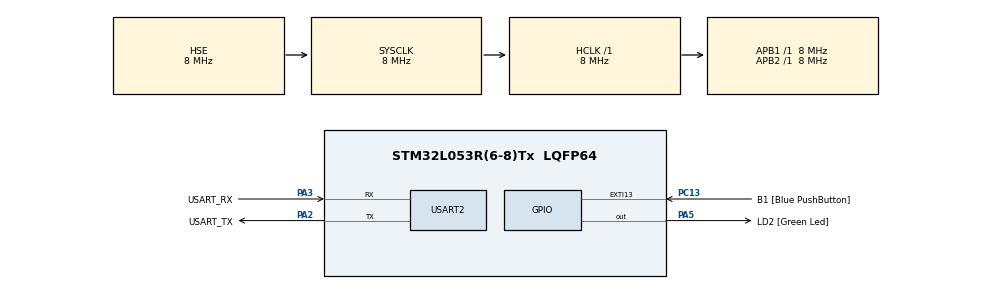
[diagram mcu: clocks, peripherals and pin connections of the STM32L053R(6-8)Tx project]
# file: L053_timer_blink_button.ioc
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Mcu.Family=STM32L0
Mcu.Name=STM32L053R(6-8)Tx
Mcu.Package=LQFP64
NVIC.TIM6_DAC_IRQn=true\:0\:0\:false\:false\:true\:true\:true
PA13.GPIO_Label=TMS
PA13.Mode=Serial_Wire
PA13.Signal=SYS_SWDIO
PA14.GPIO_Label=TCK
PA14.Mode=Serial_Wire
PA14.Signal=SYS_SWCLK
PA2.GPIO_Label=USART_TX
PA2.Mode=Asynchronous
PA2.Signal=USART2_TX
PA3.GPIO_Label=USART_RX
PA3.Mode=Asynchronous
PA3.Signal=USART2_RX
PA5.GPIO_Label=LD2 [Green Led]
PA5.Signal=GPIO_Output
PC13.GPIO_Label=B1 [Blue PushButton]
PC13.GPIO_ModeDefaultEXTI=GPIO_MODE_IT_FALLING
PC13.GPIO_PuPd=GPIO_PULLUP
PC13.Signal=GPXTI13
PC14-OSC32_IN.Mode=LSE-External-Oscillator
PC14-OSC32_IN.Signal=RCC_OSC32_IN
PC15-OSC32_OUT.Mode=LSE-External-Oscillator
PC15-OSC32_OUT.Signal=RCC_OSC32_OUT
PH0-OSC_IN.Mode=HSE-External-Clock-Source
PH0-OSC_IN.Signal=RCC_OSC_IN
PH1-OSC_OUT.Signal=RCC_OSC_OUT
ProjectManager.HeapSize=0x200
ProjectManager.StackSize=0x400
ProjectManager.TargetToolchain=STM32CubeIDE
RCC.AHBFreq_Value=8000000
RCC.APB1Freq_Value=8000000
RCC.APB1TimFreq_Value=8000000
RCC.APB2Freq_Value=8000000
RCC.APB2TimFreq_Value=8000000
RCC.HCLKFreq_Value=8000000
RCC.HSE_VALUE=8000000
RCC.HSI16_VALUE=16000000
RCC.HSI48_VALUE=48000000
RCC.HSI_VALUE=16000000
RCC.MSI_VALUE=2097000
RCC.PLLMUL=RCC_PLLMUL_4
RCC.SYSCLKFreq_VALUE=8000000
RCC.SYSCLKSource=RCC_SYSCLKSOURCE_HSE
RCC.VCOOutputFreq_Value=64000000
TIM6.Period=100
TIM6.Prescaler=8000
USART2.VirtualMode-Asynchronous=VM_ASYNC
VP_TIM6_VS_ClockSourceINT.Mode=Enable_Timer
board=NUCLEO-L053R8

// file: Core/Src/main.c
/* USER CODE BEGIN Header */
/**
  ******************************************************************************
  * @file           : main.c
  * @brief          : Main program body
  ******************************************************************************
  * @attention
  *
  * <h2><center>&copy; Copyright (c) 2020 STMicroelectronics.
  * All rights reserved.</center></h2>
  *
  * This software component is licensed by ST under BSD 3-Clause license,
  * the "License"; You may not use this file except in compliance with the
  * License. You may obtain a copy of the License at:
  *                        opensource.org/licenses/BSD-3-Clause
  *
  ******************************************************************************
  */
/* USER CODE END Header */

#include "main.h"

TIM_HandleTypeDef htim6;

UART_HandleTypeDef huart2;

void SystemClock_Config(void);
static void MX_GPIO_Init(void);
static void MX_USART2_UART_Init(void);
static void MX_TIM6_Init(void);

/* USER CODE BEGIN 0 */
int count = 0, x = 0;
/* USER CODE END 0 */

int main(void)
{

  /* MCU Configuration--------------------------------------------------------*/

  /* Reset of all peripherals, Initializes the Flash interface and the Systick. */
  HAL_Init();

  /* Configure the system clock */
  SystemClock_Config();

  /* Initialize all configured peripherals */
  MX_GPIO_Init();
  MX_USART2_UART_Init();
  MX_TIM6_Init();
  /* USER CODE BEGIN 2 */
  HAL_TIM_Base_Start_IT(&htim6);
  /* USER CODE END 2 */

  /* Infinite loop */
  /* USER CODE BEGIN WHILE */
  while (1)
  {
	  if(HAL_GPIO_ReadPin(B1_GPIO_Port, B1_Pin) == 0)
	  {
		  x = 1;
	  }
	  else
	  {
		  x = 5;
	  }
    /* USER CODE END WHILE */

  }
}

void SystemClock_Config(void)
{
  RCC_OscInitTypeDef RCC_OscInitStruct = {0};
  RCC_ClkInitTypeDef RCC_ClkInitStruct = {0};
  RCC_PeriphCLKInitTypeDef PeriphClkInit = {0};

  /** Configure the main internal regulator output voltage
  */
  __HAL_PWR_VOLTAGESCALING_CONFIG(PWR_REGULATOR_VOLTAGE_SCALE1);
  /** Initializes the CPU, AHB and APB busses clocks
  */
  RCC_OscInitStruct.OscillatorType = RCC_OSCILLATORTYPE_HSE;
  RCC_OscInitStruct.HSEState = RCC_HSE_BYPASS;
  RCC_OscInitStruct.PLL.PLLState = RCC_PLL_NONE;
  if (HAL_RCC_OscConfig(&RCC_OscInitStruct) != HAL_OK)
  {
    Error_Handler();
  }
  /** Initializes the CPU, AHB and APB busses clocks
  */
  RCC_ClkInitStruct.ClockType = RCC_CLOCKTYPE_HCLK|RCC_CLOCKTYPE_SYSCLK
                              |RCC_CLOCKTYPE_PCLK1|RCC_CLOCKTYPE_PCLK2;
  RCC_ClkInitStruct.SYSCLKSource = RCC_SYSCLKSOURCE_HSE;
  RCC_ClkInitStruct.AHBCLKDivider = RCC_SYSCLK_DIV1;
  RCC_ClkInitStruct.APB1CLKDivider = RCC_HCLK_DIV1;
  RCC_ClkInitStruct.APB2CLKDivider = RCC_HCLK_DIV1;

  if (HAL_RCC_ClockConfig(&RCC_ClkInitStruct, FLASH_LATENCY_0) != HAL_OK)
  {
    Error_Handler();
  }
  PeriphClkInit.PeriphClockSelection = RCC_PERIPHCLK_USART2;
  PeriphClkInit.Usart2ClockSelection = RCC_USART2CLKSOURCE_PCLK1;
  if (HAL_RCCEx_PeriphCLKConfig(&PeriphClkInit) != HAL_OK)
  {
    Error_Handler();
  }
}

static void MX_TIM6_Init(void)
{

  TIM_MasterConfigTypeDef sMasterConfig = {0};

  htim6.Instance = TIM6;
  htim6.Init.Prescaler = 8000;
  htim6.Init.CounterMode = TIM_COUNTERMODE_UP;
  htim6.Init.Period = 100;
  htim6.Init.AutoReloadPreload = TIM_AUTORELOAD_PRELOAD_DISABLE;
  if (HAL_TIM_Base_Init(&htim6) != HAL_OK)
  {
    Error_Handler();
  }
  sMasterConfig.MasterOutputTrigger = TIM_TRGO_RESET;
  sMasterConfig.MasterSlaveMode = TIM_MASTERSLAVEMODE_DISABLE;
  if (HAL_TIMEx_MasterConfigSynchronization(&htim6, &sMasterConfig) != HAL_OK)
  {
    Error_Handler();
  }

}

static void MX_USART2_UART_Init(void)
{

  huart2.Instance = USART2;
  huart2.Init.BaudRate = 115200;
  huart2.Init.WordLength = UART_WORDLENGTH_8B;
  huart2.Init.StopBits = UART_STOPBITS_1;
  huart2.Init.Parity = UART_PARITY_NONE;
  huart2.Init.Mode = UART_MODE_TX_RX;
  huart2.Init.HwFlowCtl = UART_HWCONTROL_NONE;
  huart2.Init.OverSampling = UART_OVERSAMPLING_16;
  huart2.Init.OneBitSampling = UART_ONE_BIT_SAMPLE_DISABLE;
  huart2.AdvancedInit.AdvFeatureInit = UART_ADVFEATURE_NO_INIT;
  if (HAL_UART_Init(&huart2) != HAL_OK)
  {
    Error_Handler();
  }

}

static void MX_GPIO_Init(void)
{
  GPIO_InitTypeDef GPIO_InitStruct = {0};

  /* GPIO Ports Clock Enable */
  __HAL_RCC_GPIOC_CLK_ENABLE();
  __HAL_RCC_GPIOH_CLK_ENABLE();
  __HAL_RCC_GPIOA_CLK_ENABLE();

  /*Configure GPIO pin Output Level */
  HAL_GPIO_WritePin(LD2_GPIO_Port, LD2_Pin, GPIO_PIN_RESET);

  /*Configure GPIO pin : B1_Pin */
  GPIO_InitStruct.Pin = B1_Pin;
  GPIO_InitStruct.Mode = GPIO_MODE_IT_FALLING;
  GPIO_InitStruct.Pull = GPIO_PULLUP;
  HAL_GPIO_Init(B1_GPIO_Port, &GPIO_InitStruct);

  /*Configure GPIO pin : LD2_Pin */
  GPIO_InitStruct.Pin = LD2_Pin;
  GPIO_InitStruct.Mode = GPIO_MODE_OUTPUT_PP;
  GPIO_InitStruct.Pull = GPIO_NOPULL;
  GPIO_InitStruct.Speed = GPIO_SPEED_FREQ_LOW;
  HAL_GPIO_Init(LD2_GPIO_Port, &GPIO_InitStruct);

}

/* USER CODE BEGIN 4 */
void HAL_TIM_PeriodElapsedCallback(TIM_HandleTypeDef *htim)
{
	if (htim->Instance == TIM6)
	{
		count++;
		if(count>=x)
		{
			count=0;
			HAL_UART_Transmit(&huart2, (uint8_t*)"LED TOOGLED\r\n", 13, 100);
			HAL_GPIO_TogglePin(LD2_GPIO_Port, LD2_Pin);
		}
	}
}
/* USER CODE END 4 */

void Error_Handler(void)
{
}

/************************ (C) COPYRIGHT STMicroelectronics *****END OF FILE****/
